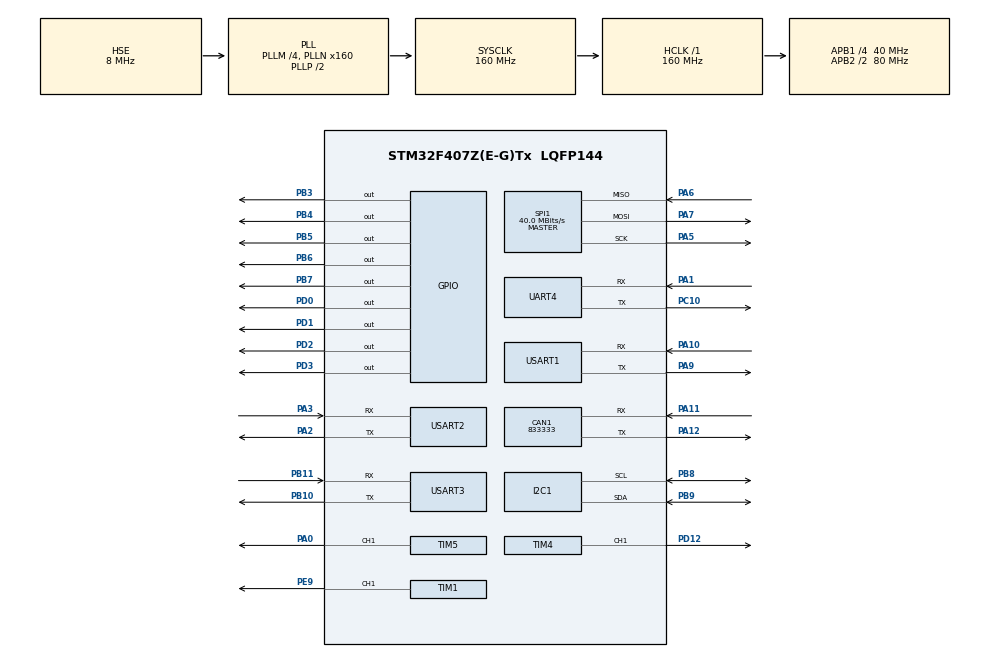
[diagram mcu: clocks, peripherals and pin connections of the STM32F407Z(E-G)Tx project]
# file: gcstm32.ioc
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CAN1.CalculateBaudRate=833333
CAN1.CalculateTimeBit=1200
CAN1.CalculateTimeQuantum=400.0
Mcu.Family=STM32F4
Mcu.Name=STM32F407Z(E-G)Tx
Mcu.Package=LQFP144
NVIC.PriorityGroup=NVIC_PRIORITYGROUP_4
NVIC.TIM2_IRQn=true\:2\:0\:true\:false\:true\:true\:true\:true
PA0-WKUP.Signal=S_TIM5_CH1
PA1.Mode=Asynchronous
PA1.Signal=UART4_RX
PA10.Mode=Asynchronous
PA10.Signal=USART1_RX
PA11.Mode=CAN_Activate
PA11.Signal=CAN1_RX
PA12.Mode=CAN_Activate
PA12.Signal=CAN1_TX
PA13.Mode=Serial_Wire
PA13.Signal=SYS_JTMS-SWDIO
PA14.Mode=Serial_Wire
PA14.Signal=SYS_JTCK-SWCLK
PA2.Mode=Asynchronous
PA2.Signal=USART2_TX
PA3.Mode=Asynchronous
PA3.Signal=USART2_RX
PA5.Mode=Full_Duplex_Master
PA5.Signal=SPI1_SCK
PA6.Mode=Full_Duplex_Master
PA6.Signal=SPI1_MISO
PA7.Mode=Full_Duplex_Master
PA7.Signal=SPI1_MOSI
PA9.Mode=Asynchronous
PA9.Signal=USART1_TX
PB10.Mode=Asynchronous
PB10.Signal=USART3_TX
PB11.Mode=Asynchronous
PB11.Signal=USART3_RX
PB3.GPIO_ModeDefaultOutputPP=GPIO_MODE_OUTPUT_PP
PB3.GPIO_PuPd=GPIO_PULLUP
PB3.GPIO_Speed=GPIO_SPEED_FREQ_HIGH
PB3.PinState=GPIO_PIN_RESET
PB3.Signal=GPIO_Output
PB4.GPIO_ModeDefaultOutputPP=GPIO_MODE_OUTPUT_PP
PB4.GPIO_PuPd=GPIO_PULLUP
PB4.GPIO_Speed=GPIO_SPEED_FREQ_HIGH
PB4.PinState=GPIO_PIN_RESET
PB4.Signal=GPIO_Output
PB5.GPIO_ModeDefaultOutputPP=GPIO_MODE_OUTPUT_PP
PB5.GPIO_PuPd=GPIO_PULLUP
PB5.GPIO_Speed=GPIO_SPEED_FREQ_HIGH
PB5.PinState=GPIO_PIN_RESET
PB5.Signal=GPIO_Output
PB6.GPIO_ModeDefaultOutputPP=GPIO_MODE_OUTPUT_PP
PB6.GPIO_PuPd=GPIO_PULLUP
PB6.GPIO_Speed=GPIO_SPEED_FREQ_HIGH
PB6.PinState=GPIO_PIN_RESET
PB6.Signal=GPIO_Output
PB7.GPIO_ModeDefaultOutputPP=GPIO_MODE_OUTPUT_PP
PB7.GPIO_PuPd=GPIO_PULLUP
PB7.GPIO_Speed=GPIO_SPEED_FREQ_HIGH
PB7.PinState=GPIO_PIN_RESET
PB7.Signal=GPIO_Output
PB8.Mode=I2C
PB8.Signal=I2C1_SCL
PB9.Mode=I2C
PB9.Signal=I2C1_SDA
PC10.Mode=Asynchronous
PC10.Signal=UART4_TX
PD0.GPIO_ModeDefaultOutputPP=GPIO_MODE_OUTPUT_PP
PD0.GPIO_PuPd=GPIO_PULLUP
PD0.GPIO_Speed=GPIO_SPEED_FREQ_HIGH
PD0.PinState=GPIO_PIN_RESET
PD0.Signal=GPIO_Output
PD1.GPIO_ModeDefaultOutputPP=GPIO_MODE_OUTPUT_PP
PD1.GPIO_PuPd=GPIO_PULLUP
PD1.GPIO_Speed=GPIO_SPEED_FREQ_HIGH
PD1.PinState=GPIO_PIN_RESET
PD1.Signal=GPIO_Output
PD12.Signal=S_TIM4_CH1
PD2.GPIO_ModeDefaultOutputPP=GPIO_MODE_OUTPUT_PP
PD2.GPIO_PuPd=GPIO_PULLUP
PD2.GPIO_Speed=GPIO_SPEED_FREQ_HIGH
PD2.PinState=GPIO_PIN_RESET
PD2.Signal=GPIO_Output
PD3.GPIO_ModeDefaultOutputPP=GPIO_MODE_OUTPUT_PP
PD3.GPIO_PuPd=GPIO_PULLUP
PD3.GPIO_Speed=GPIO_SPEED_FREQ_HIGH
PD3.PinState=GPIO_PIN_RESET
PD3.Signal=GPIO_Output
PE9.Signal=S_TIM1_CH1
PH0-OSC_IN.Mode=HSE-External-Oscillator
PH0-OSC_IN.Signal=RCC_OSC_IN
PH1-OSC_OUT.Mode=HSE-External-Oscillator
PH1-OSC_OUT.Signal=RCC_OSC_OUT
ProjectManager.HeapSize=0x200
ProjectManager.StackSize=0x400
ProjectManager.TargetToolchain=MDK-ARM V5.32
RCC.48MHZClocksFreq_Value=80000000
RCC.AHBFreq_Value=160000000
RCC.APB1CLKDivider=RCC_HCLK_DIV4
RCC.APB1Freq_Value=40000000
RCC.APB1TimFreq_Value=80000000
RCC.APB2CLKDivider=RCC_HCLK_DIV2
RCC.APB2Freq_Value=80000000
RCC.APB2TimFreq_Value=160000000
RCC.CortexFreq_Value=160000000
RCC.HCLKFreq_Value=160000000
RCC.HSE_VALUE=8000000
RCC.HSI_VALUE=16000000
RCC.LSE_VALUE=32768
RCC.PLLM=4
RCC.PLLN=160
RCC.PLLSourceVirtual=RCC_PLLSOURCE_HSE
RCC.SYSCLKFreq_VALUE=160000000
RCC.SYSCLKSource=RCC_SYSCLKSOURCE_PLLCLK
RCC.VCOOutputFreq_Value=320000000
SH.S_TIM1_CH1.0=TIM1_CH1,Output Compare1 CH1
SH.S_TIM4_CH1.0=TIM4_CH1,Output Compare1 CH1
SH.S_TIM5_CH1.0=TIM5_CH1,Output Compare1 CH1
SPI1.CalculateBaudRate=40.0 MBits/s
SPI1.Direction=SPI_DIRECTION_2LINES
SPI1.Mode=SPI_MODE_MASTER
SPI1.VirtualType=VM_MASTER
TIM1.Channel-Output\ Compare1\ CH1=TIM_CHANNEL_1
TIM1.Prescaler=159
TIM2.Channel-PWM\ Generation1\ No\ Output=TIM_CHANNEL_1
TIM2.Period=4
TIM2.Prescaler=79
TIM4.Channel-Output\ Compare1\ CH1=TIM_CHANNEL_1
TIM5.Channel-Output\ Compare1\ CH1=TIM_CHANNEL_1
UART4.VirtualMode=Asynchronous
USART1.VirtualMode=VM_ASYNC
USART2.VirtualMode=VM_ASYNC
USART3.VirtualMode=VM_ASYNC
VP_TIM2_VS_ClockSourceINT.Mode=Internal
VP_TIM2_VS_no_output1.Mode=PWM Generation1 No Output
board=custom

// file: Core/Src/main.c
/* USER CODE BEGIN Header */
/**
  ******************************************************************************
  * @file           : main.c
  * @brief          : Main program body
  ******************************************************************************
  * @attention
  *
  * Copyright (c) 2026 STMicroelectronics.
  * All rights reserved.
  *
  * This software is licensed under terms that can be found in the LICENSE file
  * in the root directory of this software component.
  * If no LICENSE file comes with this software, it is provided AS-IS.
  *
  ******************************************************************************
  */
/* USER CODE END Header */
#include "main.h"
#include "can.h"
#include "i2c.h"
#include "spi.h"
#include "tim.h"
#include "usart.h"
#include "gpio.h"

/* USER CODE BEGIN Includes */
#include <stdio.h>
#include "chassis_ctrl.h"
#include "openmv_ctrl.h"
#include "barcode_scanner.h"
/* USER CODE END Includes */

void SystemClock_Config(void);

/* USER CODE BEGIN 0 */

extern UART_HandleTypeDef huart1;

int fputc(int ch, FILE *f) {
    uint8_t c = ch;
    HAL_UART_Transmit(&huart2, &c, 1, 0xFFFF);
    return ch;
}

// ============================================================
// ?? HARDWARE WIRING GUIDE (Common-Cathode Configuration)
// ============================================================
// 1. Alarm Wires (AL+ / AL-): Leave FLOATING / UNCONNECTED.
// 2. Enable Wires (EN+): Twist all 4 motor EN+ wires together -> Connect to STM32 PB3.
//    Enable Wires (EN-): Twist all 4 motor EN- wires together -> Connect to STM32 GND.
// 3. Pulse Wires (PU+):
//    Motor 1 -> PB4 | Motor 2 -> PB6 | Motor 3 -> PD0 | Motor 4 -> PD2
//    Pulse Wires (PU-): Twist all 4 motor PU- wires together -> Connect to STM32 GND.
// 4. Direction Wires (DR+):
//    Motor 1 -> PB5 | Motor 2 -> PB7 | Motor 3 -> PD1 | Motor 4 -> PD3
//    Direction Wires (DR-): Twist all 4 motor DR- wires together -> Connect to STM32 GND.
// 5. Power: 24VDC to +VDC/GND. WARNING: Verify polarity before powering on!
// 6. DIP Switches: SW1~SW4 MUST be set to ON/ON/ON/ON (400 Pulse/Rev).
// ============================================================

/********************************************************************
 * Function Call Guide (in main.c)
 ********************************************************************
 * 1. chassis_move(float dist_x, float dist_y, float speed)
 *    - Omnidirectional movement (forward, backward, left, right, diagonal)
 *    - dist_x:  left(negative) / right(positive), unit: meter
 *    - dist_y:  backward(negative) / forward(positive), unit: meter
 *    - speed:   movement speed, recommended: 0.3 ~ 1.2
 *
 *    Examples:
 *    chassis_move(0,    0.5f, 0.8f);   // Move forward 0.5m
 *    chassis_move(0,   -0.3f, 0.8f);   // Move backward 0.3m
 *    chassis_move(0.4f, 0,    0.8f);   // Move right 0.4m
 *    chassis_move(-0.4f,0,    0.8f);   // Move left 0.4m
 *    chassis_move(0.3f, 0.5f, 0.8f);   // Move forward-right diagonally
 *
 * 2. chassis_rotate(int8_t dir, uint16_t angle, float speed)
 *    - In-place rotation (only 90/180/360 degrees supported)
 *    - dir:     1 = clockwise,  -1 = counterclockwise, 0 = clockwise
 *    - angle:   only 90 / 180 / 360
 *    - speed:   rotation speed, recommended: 0.3 ~ 1.0
 *
 *    Examples:
 *    chassis_rotate(1,   90, 0.8f);    // Rotate 90� clockwise
 *    chassis_rotate(-1,  90, 0.8f);    // Rotate 90� counterclockwise
 *    chassis_rotate(1,  180, 0.8f);    // Rotate 180� clockwise
 *    chassis_rotate(1,  360, 0.8f);    // Rotate 360� clockwise
 ********************************************************************/

/* USER CODE END 0 */

int main(void)
{

  /* MCU Configuration--------------------------------------------------------*/

  /* Reset of all peripherals, Initializes the Flash interface and the Systick. */
  HAL_Init();

  /* USER CODE BEGIN Init */
	//chassis_init();
	//OpenMV_Init();

  /* USER CODE END Init */

  /* Configure the system clock */
  SystemClock_Config();

  /* Initialize all configured peripherals */
  MX_GPIO_Init();
  MX_USART1_UART_Init();
  MX_USART3_UART_Init();
  MX_CAN1_Init();
  MX_I2C1_Init();
  MX_SPI1_Init();
  MX_TIM1_Init();
  MX_TIM2_Init();
  MX_TIM4_Init();
  MX_TIM5_Init();
  MX_UART4_Init();
  MX_USART2_UART_Init();
  /* USER CODE BEGIN 2 */
	chassis_init();        // ????

  /* USER CODE END 2 */

  /* Infinite loop */
  /* USER CODE BEGIN WHILE */
  while (1)
  {
		/*
		uint8_t result = OpenMV_Run_Align(1, 3000);

		if(result == 1)
		{
			// ??:OpenMV ?? DONE
			HAL_UART_Transmit(&huart1, (uint8_t*)"OpenMV OK\r\n", 10, HAL_MAX_DELAY);
		}
		else
		{
			// ??:??
			HAL_UART_Transmit(&huart1, (uint8_t*)"OpenMV TIMEOUT\r\n", 15, HAL_MAX_DELAY);
		}*/
		// Rotate 90 degrees CLOCKWISE

		//HAL_Delay(5000);
		//chassis_rotate(-1, 90, 0.3f);

		/*HAL_Delay(5000);
		chassis_move(1.0f, 0.0f, 0.3f);
		HAL_Delay(2000);
		chassis_move(-1.0f, 0.0f, 0.3f);
		HAL_Delay(2000);
		chassis_move(0.0f, 1.0f, 0.3f);
		HAL_Delay(2000);
		chassis_move(0.0f, -1.0f, 0.3f);
		HAL_Delay(2000);
		chassis_rotate(1, 90, 0.1f);
		HAL_Delay(2000);
		chassis_rotate(-1, 90, 0.1f);*/
		__HAL_TIM_SET_COMPARE(&htim1, TIM_CHANNEL_1, 1500);
		HAL_Delay(500); // 等待舵机到位

		// 转到15°
		__HAL_TIM_SET_COMPARE(&htim1, TIM_CHANNEL_1, 667);
		HAL_Delay(500); // 等待舵机到位

		/*
		char *barcode = GM65_ScanOnce();

        // 3. ?????? g_barcode_result(????)
        if (barcode != NULL)
        {
				if (strlen(g_barcode_result) > 10)
            {
                HAL_UART_Transmit(&huart1, (uint8_t*)"??????10\r\n", 16, 100);
            }
        }
        else
        {
            // ??????,????????,????
            HAL_UART_Transmit(&huart1, (uint8_t*)"??????\r\n", 12, 100);
        }

        HAL_Delay(1000);   // ??1?,??????
    }
}
		*/

    /* USER CODE END WHILE */

  }
}

void SystemClock_Config(void)
{
  RCC_OscInitTypeDef RCC_OscInitStruct = {0};
  RCC_ClkInitTypeDef RCC_ClkInitStruct = {0};

  /** Configure the main internal regulator output voltage
  */
  __HAL_RCC_PWR_CLK_ENABLE();
  __HAL_PWR_VOLTAGESCALING_CONFIG(PWR_REGULATOR_VOLTAGE_SCALE1);

  /** Initializes the RCC Oscillators according to the specified parameters
  * in the RCC_OscInitTypeDef structure.
  */
  RCC_OscInitStruct.OscillatorType = RCC_OSCILLATORTYPE_HSE;
  RCC_OscInitStruct.HSEState = RCC_HSE_ON;
  RCC_OscInitStruct.PLL.PLLState = RCC_PLL_ON;
  RCC_OscInitStruct.PLL.PLLSource = RCC_PLLSOURCE_HSE;
  RCC_OscInitStruct.PLL.PLLM = 4;
  RCC_OscInitStruct.PLL.PLLN = 160;
  RCC_OscInitStruct.PLL.PLLP = RCC_PLLP_DIV2;
  RCC_OscInitStruct.PLL.PLLQ = 4;
  if (HAL_RCC_OscConfig(&RCC_OscInitStruct) != HAL_OK)
  {
    Error_Handler();
  }

  /** Initializes the CPU, AHB and APB buses clocks
  */
  RCC_ClkInitStruct.ClockType = RCC_CLOCKTYPE_HCLK|RCC_CLOCKTYPE_SYSCLK
                              |RCC_CLOCKTYPE_PCLK1|RCC_CLOCKTYPE_PCLK2;
  RCC_ClkInitStruct.SYSCLKSource = RCC_SYSCLKSOURCE_PLLCLK;
  RCC_ClkInitStruct.AHBCLKDivider = RCC_SYSCLK_DIV1;
  RCC_ClkInitStruct.APB1CLKDivider = RCC_HCLK_DIV4;
  RCC_ClkInitStruct.APB2CLKDivider = RCC_HCLK_DIV2;

  if (HAL_RCC_ClockConfig(&RCC_ClkInitStruct, FLASH_LATENCY_5) != HAL_OK)
  {
    Error_Handler();
  }
}

void Error_Handler(void)
{
  __disable_irq();
  while (1)
  {
  }
}
